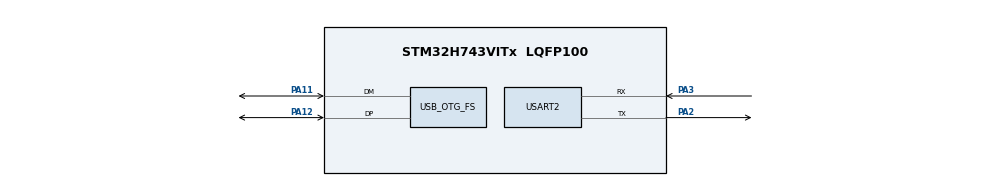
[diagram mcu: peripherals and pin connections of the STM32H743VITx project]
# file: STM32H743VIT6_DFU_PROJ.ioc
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Dma.Request0=USART2_RX
Dma.Request1=USART2_TX
Dma.USART2_RX.0.Direction=DMA_PERIPH_TO_MEMORY
Dma.USART2_RX.0.EventEnable=DISABLE
Dma.USART2_RX.0.FIFOMode=DMA_FIFOMODE_DISABLE
Dma.USART2_RX.0.Instance=DMA1_Stream2
Dma.USART2_RX.0.MemDataAlignment=DMA_MDATAALIGN_BYTE
Dma.USART2_RX.0.MemInc=DMA_MINC_ENABLE
Dma.USART2_RX.0.Mode=DMA_NORMAL
Dma.USART2_RX.0.PeriphDataAlignment=DMA_PDATAALIGN_BYTE
Dma.USART2_RX.0.PeriphInc=DMA_PINC_DISABLE
Dma.USART2_RX.0.Polarity=HAL_DMAMUX_REQ_GEN_RISING
Dma.USART2_RX.0.Priority=DMA_PRIORITY_LOW
Dma.USART2_RX.0.RequestNumber=1
Dma.USART2_RX.0.SignalID=NONE
Dma.USART2_RX.0.SyncEnable=DISABLE
Dma.USART2_RX.0.SyncPolarity=HAL_DMAMUX_SYNC_NO_EVENT
Dma.USART2_RX.0.SyncRequestNumber=1
Dma.USART2_RX.0.SyncSignalID=NONE
Dma.USART2_TX.1.Direction=DMA_MEMORY_TO_PERIPH
Dma.USART2_TX.1.EventEnable=DISABLE
Dma.USART2_TX.1.FIFOMode=DMA_FIFOMODE_DISABLE
Dma.USART2_TX.1.Instance=DMA1_Stream3
Dma.USART2_TX.1.MemDataAlignment=DMA_MDATAALIGN_BYTE
Dma.USART2_TX.1.MemInc=DMA_MINC_ENABLE
Dma.USART2_TX.1.Mode=DMA_NORMAL
Dma.USART2_TX.1.PeriphDataAlignment=DMA_PDATAALIGN_BYTE
Dma.USART2_TX.1.PeriphInc=DMA_PINC_DISABLE
Dma.USART2_TX.1.Polarity=HAL_DMAMUX_REQ_GEN_RISING
Dma.USART2_TX.1.Priority=DMA_PRIORITY_LOW
Dma.USART2_TX.1.RequestNumber=1
Dma.USART2_TX.1.SignalID=NONE
Dma.USART2_TX.1.SyncEnable=DISABLE
Dma.USART2_TX.1.SyncPolarity=HAL_DMAMUX_SYNC_NO_EVENT
Dma.USART2_TX.1.SyncRequestNumber=1
Dma.USART2_TX.1.SyncSignalID=NONE
Mcu.Family=STM32H7
Mcu.Name=STM32H743VITx
Mcu.Package=LQFP100
NVIC.DMA1_Stream2_IRQn=true\:0\:0\:false\:false\:true\:false\:true
NVIC.DMA1_Stream3_IRQn=true\:0\:0\:false\:false\:true\:false\:true
NVIC.OTG_FS_IRQn=true\:0\:0\:false\:false\:true\:false\:true
NVIC.PriorityGroup=NVIC_PRIORITYGROUP_4
NVIC.USART2_IRQn=true\:0\:0\:false\:false\:true\:true\:true
PA11.Mode=Device_Only
PA11.Signal=USB_OTG_FS_DM
PA12.Mode=Device_Only
PA12.Signal=USB_OTG_FS_DP
PA13\ (JTMS/SWDIO).Mode=Serial_Wire
PA13\ (JTMS/SWDIO).Signal=DEBUG_JTMS-SWDIO
PA14\ (JTCK/SWCLK).Mode=Serial_Wire
PA14\ (JTCK/SWCLK).Signal=DEBUG_JTCK-SWCLK
PA2.Mode=Asynchronous
PA2.Signal=USART2_TX
PA3.Mode=Asynchronous
PA3.Signal=USART2_RX
PC14-OSC32_IN\ (OSC32_IN).Mode=LSE-External-Oscillator
PC14-OSC32_IN\ (OSC32_IN).Signal=RCC_OSC32_IN
PC15-OSC32_OUT\ (OSC32_OUT).Mode=LSE-External-Oscillator
PC15-OSC32_OUT\ (OSC32_OUT).Signal=RCC_OSC32_OUT
PH0-OSC_IN\ (PH0).Mode=HSE-External-Oscillator
PH0-OSC_IN\ (PH0).Signal=RCC_OSC_IN
PH1-OSC_OUT\ (PH1).Mode=HSE-External-Oscillator
PH1-OSC_OUT\ (PH1).Signal=RCC_OSC_OUT
ProjectManager.HeapSize=0x1000
ProjectManager.StackSize=0x2000
ProjectManager.TargetToolchain=EWARM V8.32
RCC.ADCFreq_Value=64500000
RCC.APB1Freq_Value=120000000
RCC.APB2Freq_Value=120000000
RCC.APB3Freq_Value=120000000
RCC.APB4Freq_Value=120000000
RCC.CortexFreq_Value=480000000
RCC.D1PPRE=RCC_APB3_DIV2
RCC.D2PPRE1=RCC_APB1_DIV2
RCC.D2PPRE2=RCC_APB2_DIV2
RCC.D3PPRE=RCC_APB4_DIV2
RCC.DIVM1=5
RCC.DIVM2=25
RCC.DIVM3=25
RCC.DIVN1=192
RCC.DIVN3=192
RCC.DIVQ3=4
RCC.DIVR1=10
RCC.HCLKFreq_Value=240000000
RCC.HPRE=RCC_HCLK_DIV2
RCC.PLL2FRACN=0
RCC.PLL3FRACN=0
RCC.PLLFRACN=0
RCC.PLLSourceVirtual=RCC_PLLSOURCE_HSE
RCC.SYSCLKFreq_VALUE=480000000
RCC.SYSCLKSource=RCC_SYSCLKSOURCE_PLLCLK
RCC.USBCLockSelection=RCC_USBCLKSOURCE_PLL3
RCC.USBFreq_Value=48000000
USART2.VirtualMode-Asynchronous=VM_ASYNC
USB_DEVICE.CLASS_NAME_FS=DFU
USB_DEVICE.USBD_DFU_APP_DEFAULT_ADD-DFU_FS=0x080A0000
USB_DEVICE.USBD_DFU_MEDIA-DFU_FS=@Internal Flash   /0x08000000/03*016Ka,01*016Kg,01*064Kg,07*128Kg,04*016Kg,01*064Kg,07*128Kg
USB_DEVICE.VirtualMode-DFU_FS=Dfu
USB_DEVICE.VirtualModeFS=Dfu_FS
USB_OTG_FS.VirtualMode=Device_Only
USB_OTG_FS.dma_enable=DISABLE
VP_USB_DEVICE_VS_USB_DEVICE_DFU_FS.Mode=DFU_FS
board=custom

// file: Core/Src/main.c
/* USER CODE BEGIN Header */
/**
  ******************************************************************************
  * @file           : main.c
  * @brief          : Main program body
  ******************************************************************************
  * @attention
  *
  * <h2><center>&copy; Copyright (c) 2021 STMicroelectronics.
  * All rights reserved.</center></h2>
  *
  * This software component is licensed by ST under Ultimate Liberty license
  * SLA0044, the "License"; You may not use this file except in compliance with
  * the License. You may obtain a copy of the License at:
  *                             www.st.com/SLA0044
  *
  ******************************************************************************
  */
/* USER CODE END Header */
#include "main.h"
#include "dma.h"
#include "usart.h"
#include "usb_device.h"
#include "gpio.h"

void SystemClock_Config(void);

int main(void)
{
  /* USER CODE BEGIN 1 */
  User_InterruptVectorTable_Move();
  /* USER CODE END 1 */

  /* MCU Configuration--------------------------------------------------------*/

  /* Reset of all peripherals, Initializes the Flash interface and the Systick. */
  HAL_Init();

  /* Configure the system clock */
  SystemClock_Config();

  /* Initialize all configured peripherals */
  MX_GPIO_Init();
  MX_DMA_Init();
  MX_USB_DEVICE_Init();
  MX_USART2_UART_Init();
  /* USER CODE BEGIN 2 */
  User_Main_Task_Init();
  /* USER CODE END 2 */

  /* Infinite loop */
  while (1)
  {

    /* USER CODE BEGIN 3 */
    User_Main_Task_Process_Loop();
  }
  /* USER CODE END 3 */
}

void SystemClock_Config(void)
{
  RCC_OscInitTypeDef RCC_OscInitStruct = {0};
  RCC_ClkInitTypeDef RCC_ClkInitStruct = {0};

  /** Supply configuration update enable
  */
  HAL_PWREx_ConfigSupply(PWR_LDO_SUPPLY);
  /** Configure the main internal regulator output voltage
  */
  __HAL_PWR_VOLTAGESCALING_CONFIG(PWR_REGULATOR_VOLTAGE_SCALE0);

  while(!__HAL_PWR_GET_FLAG(PWR_FLAG_VOSRDY)) {}
  /** Macro to configure the PLL clock source
  */
  __HAL_RCC_PLL_PLLSOURCE_CONFIG(RCC_PLLSOURCE_HSE);
  /** Initializes the RCC Oscillators according to the specified parameters
  * in the RCC_OscInitTypeDef structure.
  */
  RCC_OscInitStruct.OscillatorType = RCC_OSCILLATORTYPE_HSE;
  RCC_OscInitStruct.HSEState = RCC_HSE_ON;
  RCC_OscInitStruct.PLL.PLLState = RCC_PLL_ON;
  RCC_OscInitStruct.PLL.PLLSource = RCC_PLLSOURCE_HSE;
  RCC_OscInitStruct.PLL.PLLM = 5;
  RCC_OscInitStruct.PLL.PLLN = 192;
  RCC_OscInitStruct.PLL.PLLP = 2;
  RCC_OscInitStruct.PLL.PLLQ = 2;
  RCC_OscInitStruct.PLL.PLLR = 10;
  RCC_OscInitStruct.PLL.PLLRGE = RCC_PLL1VCIRANGE_2;
  RCC_OscInitStruct.PLL.PLLVCOSEL = RCC_PLL1VCOWIDE;
  RCC_OscInitStruct.PLL.PLLFRACN = 0;
  if (HAL_RCC_OscConfig(&RCC_OscInitStruct) != HAL_OK)
  {
    Error_Handler();
  }
  /** Initializes the CPU, AHB and APB buses clocks
  */
  RCC_ClkInitStruct.ClockType = RCC_CLOCKTYPE_HCLK|RCC_CLOCKTYPE_SYSCLK
                              |RCC_CLOCKTYPE_PCLK1|RCC_CLOCKTYPE_PCLK2
                              |RCC_CLOCKTYPE_D3PCLK1|RCC_CLOCKTYPE_D1PCLK1;
  RCC_ClkInitStruct.SYSCLKSource = RCC_SYSCLKSOURCE_PLLCLK;
  RCC_ClkInitStruct.SYSCLKDivider = RCC_SYSCLK_DIV1;
  RCC_ClkInitStruct.AHBCLKDivider = RCC_HCLK_DIV2;
  RCC_ClkInitStruct.APB3CLKDivider = RCC_APB3_DIV2;
  RCC_ClkInitStruct.APB1CLKDivider = RCC_APB1_DIV2;
  RCC_ClkInitStruct.APB2CLKDivider = RCC_APB2_DIV2;
  RCC_ClkInitStruct.APB4CLKDivider = RCC_APB4_DIV2;

  if (HAL_RCC_ClockConfig(&RCC_ClkInitStruct, FLASH_LATENCY_4) != HAL_OK)
  {
    Error_Handler();
  }
}

void Error_Handler(void)
{
  __disable_irq();
  while (1)
  {
  }
}

/************************ (C) COPYRIGHT STMicroelectronics *****END OF FILE****/
